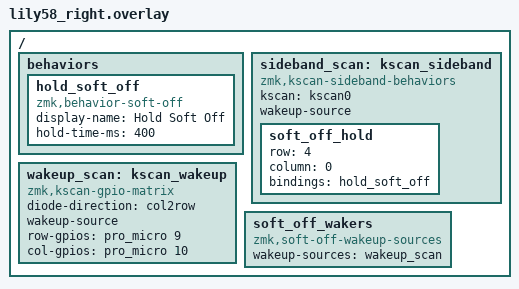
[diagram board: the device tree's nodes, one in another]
/*
 * Wakeup configuration: right side (] key = inner thumb)
 *
 * Matrix position: row 4, col 0 (local, with col-offset=6 → global col 6)
 *   row 4 = pro_micro pin 9  = gpio1 6
 *   col 0 = pro_micro pin 10 = gpio0 9
 */

#include <zephyr/dt-bindings/gpio/gpio.h>

/ {
    behaviors {
        hold_soft_off: hold_soft_off {
            compatible = "zmk,behavior-soft-off";
            #binding-cells = <0>;
            display-name = "Hold Soft Off";
            hold-time-ms = <400>;
        };
    };

    sideband_scan: kscan_sideband {
        compatible = "zmk,kscan-sideband-behaviors";
        kscan = <&kscan0>;
        wakeup-source;

        soft_off_hold {
            row = <4>;
            column = <0>;
            bindings = <&hold_soft_off>;
        };
    };

    wakeup_scan: kscan_wakeup {
        compatible = "zmk,kscan-gpio-matrix";
        diode-direction = "col2row";
        wakeup-source;

        row-gpios = <&pro_micro 9 (GPIO_ACTIVE_HIGH | GPIO_PULL_DOWN)>;
        col-gpios = <&pro_micro 10 GPIO_ACTIVE_HIGH>;
    };

    soft_off_wakers {
        compatible = "zmk,soft-off-wakeup-sources";
        wakeup-sources = <&wakeup_scan>;
    };
};
